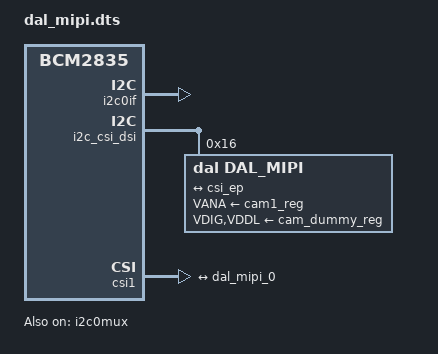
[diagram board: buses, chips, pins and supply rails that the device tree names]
// SPDX-License-Identifier: GPL-2.0-only
// Definitions for Device A-Lab camera module on VC I2C bus
/dts-v1/;
/plugin/;

/{
	compatible = "brcm,bcm2835";

	fragment@0 {
		target = <&i2c0if>;
		__overlay__ {
			status = "okay";
		};
	};

	clk_frag: fragment@1 {
		target = <&cam1_clk>;
		__overlay__ {
			status = "okay";
//			clock-frequency = <24000000>;
			clock-frequency = <100000000>;
		};
	};

	fragment@2 {
		target = <&i2c0mux>;
		__overlay__ {
			status = "okay";
		};
	};

	i2c_frag: fragment@3 {
		target = <&i2c_csi_dsi>;
		__overlay__ {
			#address-cells = <1>;
			#size-cells = <0>;
			status = "okay";

			dal_mipi: dal_mipi@16 {
				compatible = "dal,dal_mipi";
				reg = <0x16>;
				status = "okay";

				clocks = <&cam1_clk>;
				clock-names = "xclk";

				VANA-supply = <&cam1_reg>;	/* 2.8v */
				VDIG-supply = <&cam_dummy_reg>;	/* 1.8v */
				VDDL-supply = <&cam_dummy_reg>;	/* 1.2v */

				rotation = <180>;
				orientation = <2>;

				port {
					dal_mipi_0: endpoint {
						remote-endpoint = <&csi_ep>;
						clock-lanes = <0>;
						clock-noncontinuous;
					};
				};
			};

			vcm: ad5398@0c {
				compatible = "adi,ad5398";
				reg = <0x0c>;
				status = "disabled";
				VANA-supply = <&cam1_reg>;
			};
		};
	};

	csi_frag: fragment@4 {
		target = <&csi1>;
		csi: __overlay__ {
			status = "okay";
			brcm,media-controller;

			port {
				csi_ep: endpoint {
					remote-endpoint = <&dal_mipi_0>;
					clock-lanes = <0>;
					clock-noncontinuous;
				};
			};
		};
	};

	fragment@5 {
		target = <&csi_ep>;
		__overlay__ {
			data-lanes = <1>;
		};
	};

	fragment@6 {
		target = <&csi_ep>;
		__dormant__ {
			data-lanes = <1 2>;
		};
	};

	fragment@7 {
		target = <&dal_mipi_0>;
		__overlay__ {
			data-lanes = <1>;
		};
	};

	fragment@8 {
		target = <&dal_mipi_0>;
		__dormant__ {
			data-lanes = <1 2>;
		};
	};

	__overrides__ {
		2lanes = <0>, "-5+6-7+8";
      i2c-addr = <&dal_mipi>,"reg:0";
	};
};
